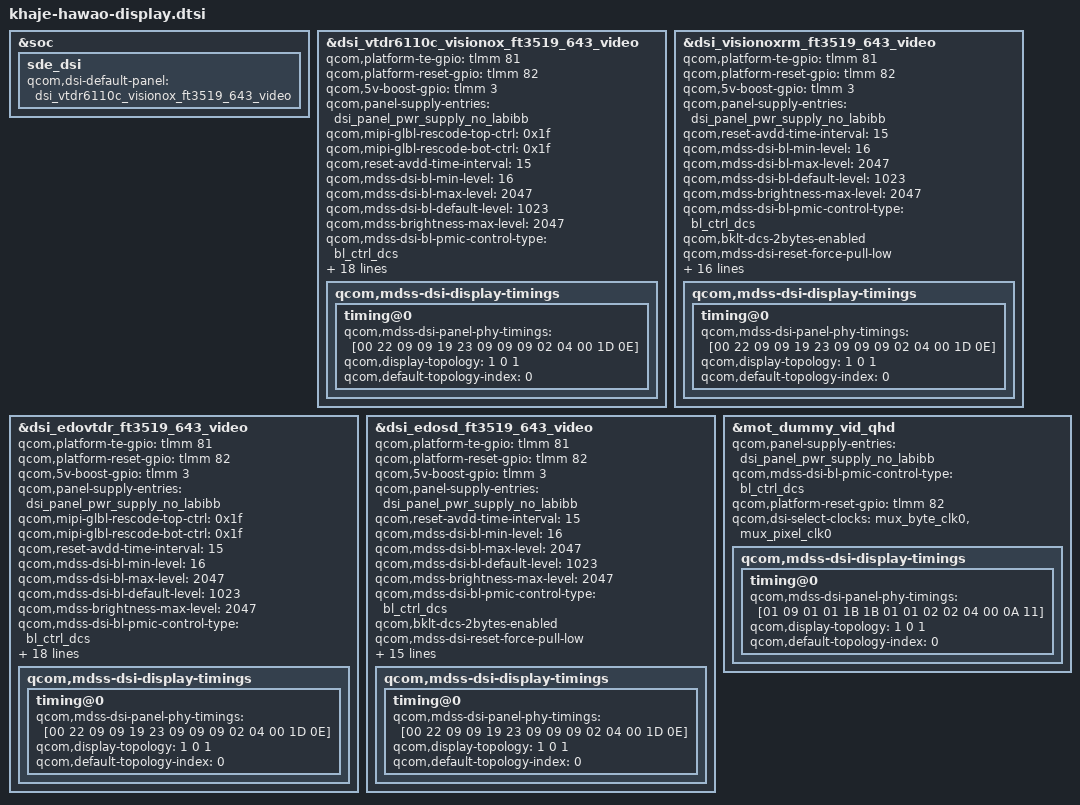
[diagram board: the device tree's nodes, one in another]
#include "dsi-panel-mot-visionox-vtdr6110c-643-1080x2400-fhp-vid.dtsi"
#include "dsi-panel-mot-visionox-rm692c9-ft3519-643-1080x2400-fhd-vid.dtsi"
#include "dsi-panel-mot-edo-vtdr6110c-ft3519-643-1080x2400-fhp-vid.dtsi"
#include "dsi-panel-mot-edo-sd5302-ft3519-643-1080x2400-fhp-vid.dtsi"
#include "dsi-panel-mot-dummy-qhd-video.dtsi"

&soc {

	sde_dsi {
		qcom,dsi-default-panel = <&dsi_vtdr6110c_visionox_ft3519_643_video>;
	};
};

&dsi_vtdr6110c_visionox_ft3519_643_video {
	qcom,platform-te-gpio = <&tlmm 81 0>;
	qcom,platform-reset-gpio = <&tlmm 82 0>;
	qcom,5v-boost-gpio = <&tlmm 3 0>;

	qcom,panel-supply-entries = <&dsi_panel_pwr_supply_no_labibb>;

	qcom,mipi-glbl-rescode-top-ctrl = <0x1f>;
	qcom,mipi-glbl-rescode-bot-ctrl = <0x1f>;
	qcom,reset-avdd-time-interval = <15>;

	qcom,mdss-dsi-bl-min-level = <16>;
	qcom,mdss-dsi-bl-max-level = <2047>;
	qcom,mdss-dsi-bl-default-level = <1023>;
	qcom,mdss-brightness-max-level = <2047>;
	qcom,mdss-dsi-bl-pmic-control-type = "bl_ctrl_dcs";
	qcom,bklt-dcs-2bytes-enabled;
	qcom,keep-regulators-on;
        qcom,mdss-dsi-reset-force-pull-low;
        qcom,disp_pre_reset;
	qcom,mdss-dsi-no-panel-on-read-support;

	qcom,esd-check-enabled;
	qcom,mdss-dsi-panel-status-check-mode = "reg_read";
	qcom,mdss-dsi-panel-status-command = [06 01 00 01 00 00 01 0a];
	qcom,mdss-dsi-panel-status-command-state = "dsi_hs_mode";
	qcom,mdss-dsi-panel-status-value = <0x9c>;
	qcom,mdss-dsi-panel-status-read-length = <1>;

	qcom,dsi-select-clocks = "mux_byte_clk0", "mux_pixel_clk0";
    qcom,mdss-dsi-t-clk-post = <0x0E>;
	qcom,mdss-dsi-t-clk-pre = <0x1D>;
	qcom,mdss-dsi-display-timings {
		timing@0 {
			qcom,mdss-dsi-panel-phy-timings = [00 22 09 09 19 23 09
				09 09 02 04 00 1D 0E];
			qcom,display-topology = <1 0 1>;
			qcom,default-topology-index = <0>;
		};
	};
};

&dsi_visionoxrm_ft3519_643_video {
	qcom,platform-te-gpio = <&tlmm 81 0>;
	qcom,platform-reset-gpio = <&tlmm 82 0>;
	qcom,5v-boost-gpio = <&tlmm 3 0>;
	qcom,panel-supply-entries = <&dsi_panel_pwr_supply_no_labibb>;
	qcom,reset-avdd-time-interval = <15>;

	qcom,mdss-dsi-bl-min-level = <16>;
	qcom,mdss-dsi-bl-max-level = <2047>;
	qcom,mdss-dsi-bl-default-level = <1023>;
	qcom,mdss-brightness-max-level = <2047>;
	qcom,mdss-dsi-bl-pmic-control-type = "bl_ctrl_dcs";
	qcom,bklt-dcs-2bytes-enabled;
	    qcom,mdss-dsi-reset-force-pull-low;
        qcom,disp_pre_reset;
	qcom,keep-regulators-on;

	qcom,mdss-dsi-no-panel-on-read-support;

	qcom,esd-check-enabled;
	qcom,mdss-dsi-panel-status-check-mode = "reg_read";
	qcom,mdss-dsi-panel-status-command = [06 01 00 01 00 00 01 0a];
	qcom,mdss-dsi-panel-status-command-state = "dsi_hs_mode";
	qcom,mdss-dsi-panel-status-value = <0x9c>;
	qcom,mdss-dsi-panel-status-read-length = <1>;

	qcom,dsi-select-clocks = "mux_byte_clk0", "mux_pixel_clk0";
	qcom,mdss-dsi-t-clk-post = <0x0E>;
	qcom,mdss-dsi-t-clk-pre = <0x1D>;
	qcom,mdss-dsi-display-timings {
		timing@0 {
			qcom,mdss-dsi-panel-phy-timings = [00 22 09 09 19 23 09
				09 09 02 04 00 1D 0E];
			qcom,display-topology = <1 0 1>;
			qcom,default-topology-index = <0>;
		};
	};
};

&dsi_edovtdr_ft3519_643_video {
	qcom,platform-te-gpio = <&tlmm 81 0>;
	qcom,platform-reset-gpio = <&tlmm 82 0>;
	qcom,5v-boost-gpio = <&tlmm 3 0>;

	qcom,panel-supply-entries = <&dsi_panel_pwr_supply_no_labibb>;

	qcom,mipi-glbl-rescode-top-ctrl = <0x1f>;
	qcom,mipi-glbl-rescode-bot-ctrl = <0x1f>;
	qcom,reset-avdd-time-interval = <15>;

	qcom,mdss-dsi-bl-min-level = <16>;
	qcom,mdss-dsi-bl-max-level = <2047>;
	qcom,mdss-dsi-bl-default-level = <1023>;
	qcom,mdss-brightness-max-level = <2047>;
	qcom,mdss-dsi-bl-pmic-control-type = "bl_ctrl_dcs";
	qcom,bklt-dcs-2bytes-enabled;
	qcom,keep-regulators-on;
	qcom,mdss-dsi-reset-force-pull-low;
    qcom,disp_pre_reset;
	qcom,mdss-dsi-no-panel-on-read-support;

	qcom,esd-check-enabled;
	qcom,mdss-dsi-panel-status-check-mode = "reg_read";
	qcom,mdss-dsi-panel-status-command = [06 01 00 01 00 00 01 0a];
	qcom,mdss-dsi-panel-status-command-state = "dsi_hs_mode";
	qcom,mdss-dsi-panel-status-value = <0x9c>;
	qcom,mdss-dsi-panel-status-read-length = <1>;

	qcom,dsi-select-clocks = "mux_byte_clk0", "mux_pixel_clk0";
	qcom,mdss-dsi-t-clk-post = <0x0E>;
	qcom,mdss-dsi-t-clk-pre = <0x1D>;
	qcom,mdss-dsi-display-timings {
		timing@0 {
			qcom,mdss-dsi-panel-phy-timings = [00 22 09 09 19 23 09
				09 09 02 04 00 1D 0E];
			qcom,display-topology = <1 0 1>;
			qcom,default-topology-index = <0>;
		};
	};
};

&dsi_edosd_ft3519_643_video {
	qcom,platform-te-gpio = <&tlmm 81 0>;
	qcom,platform-reset-gpio = <&tlmm 82 0>;
	qcom,5v-boost-gpio = <&tlmm 3 0>;

	qcom,panel-supply-entries = <&dsi_panel_pwr_supply_no_labibb>;
	qcom,reset-avdd-time-interval = <15>;

	qcom,mdss-dsi-bl-min-level = <16>;
	qcom,mdss-dsi-bl-max-level = <2047>;
	qcom,mdss-dsi-bl-default-level = <1023>;
	qcom,mdss-brightness-max-level = <2047>;
	qcom,mdss-dsi-bl-pmic-control-type = "bl_ctrl_dcs";
	qcom,bklt-dcs-2bytes-enabled;
	    qcom,mdss-dsi-reset-force-pull-low;
        qcom,disp_pre_reset;
	qcom,keep-regulators-on;
	qcom,mdss-dsi-no-panel-on-read-support;

	//qcom,esd-check-enabled;
	qcom,mdss-dsi-panel-status-check-mode = "reg_read";
	qcom,mdss-dsi-panel-status-command = [06 01 00 01 00 00 01 0a];
	qcom,mdss-dsi-panel-status-command-state = "dsi_hs_mode";
	qcom,mdss-dsi-panel-status-value = <0x9c>;
	qcom,mdss-dsi-panel-status-read-length = <1>;

	qcom,dsi-select-clocks = "mux_byte_clk0", "mux_pixel_clk0";
	qcom,mdss-dsi-t-clk-post = <0x0E>;
	qcom,mdss-dsi-t-clk-pre = <0x1D>;
	qcom,mdss-dsi-display-timings {
		timing@0 {
			qcom,mdss-dsi-panel-phy-timings = [00 22 09 09 19 23 09
				09 09 02 04 00 1D 0E];
			qcom,display-topology = <1 0 1>;
			qcom,default-topology-index = <0>;
		};
	};
};

&mot_dummy_vid_qhd {
	qcom,panel-supply-entries = <&dsi_panel_pwr_supply_no_labibb>;
	qcom,mdss-dsi-bl-pmic-control-type = "bl_ctrl_dcs";
	qcom,platform-reset-gpio = <&tlmm 82 0>;

	qcom,dsi-select-clocks = "mux_byte_clk0", "mux_pixel_clk0";
	qcom,mdss-dsi-display-timings {
		timing@0 {
			qcom,mdss-dsi-panel-phy-timings = [01 09 01 01 1B 1B 01
					01 02 02 04 00 0A 11];
			qcom,display-topology = <1 0 1>;
			qcom,default-topology-index = <0>;
		};
	};
};


